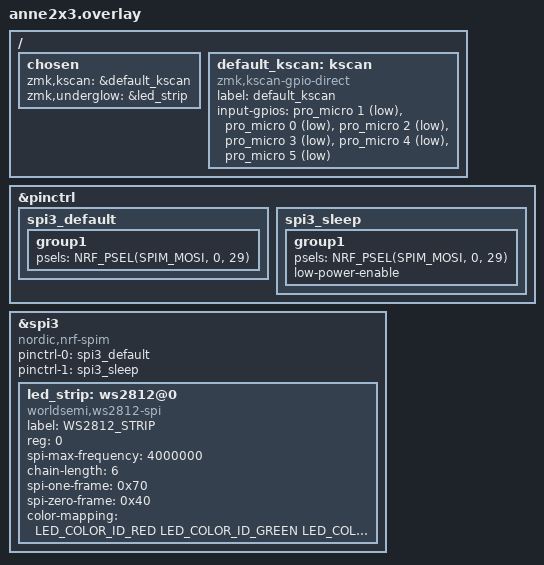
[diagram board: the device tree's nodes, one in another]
/*
 * Copyright (c) 2024 The ZMK Contributors
 *
 * SPDX-License-Identifier: MIT
 */

#include <dt-bindings/led/led.h> // Necesario para LED_COLOR_ID_XXX

/ {
    chosen {
        zmk,kscan = &default_kscan;
        zmk,underglow = &led_strip; // Apunta a la etiqueta de la tira de LEDs definida abajo
    };

    default_kscan: kscan {
        compatible = "zmk,kscan-gpio-direct";
        label = "default_kscan";
        input-gpios =
            <&pro_micro 1  (GPIO_ACTIVE_LOW | GPIO_PULL_UP)>,
            <&pro_micro 0  (GPIO_ACTIVE_LOW | GPIO_PULL_UP)>,
            <&pro_micro 2  (GPIO_ACTIVE_LOW | GPIO_PULL_UP)>,
            <&pro_micro 3  (GPIO_ACTIVE_LOW | GPIO_PULL_UP)>,
            <&pro_micro 4  (GPIO_ACTIVE_LOW | GPIO_PULL_UP)>,
            <&pro_micro 5  (GPIO_ACTIVE_LOW | GPIO_PULL_UP)>;
    };
};

// --- Sección para LEDs WS2812B usando driver SPI ---

// Configuración del pinctrl para el periférico SPI3
// Se asigna el pin P0.29 como MOSI para spi3.
&pinctrl {
    spi3_default: spi3_default {
        group1 {
            // P0.29 como MOSI (Master Out Slave In) del SPIM3
            psels = <NRF_PSEL(SPIM_MOSI, 0, 29)>; // <--- CORREGIDO A PIN 29
        };
    };

    spi3_sleep: spi3_sleep {
        group1 {
            psels = <NRF_PSEL(SPIM_MOSI, 0, 29)>; // <--- CORREGIDO A PIN 29
            low-power-enable; // Configuración para bajo consumo
        };
    };
};

// Habilitación y configuración del periférico SPI3
&spi3 {
    compatible = "nordic,nrf-spim"; // Compatible para el controlador SPIM de Nordic
    status = "okay"; // Habilitar el periférico SPI3

    // Asignar los pinctrl definidos arriba
    pinctrl-0 = <&spi3_default>;
    pinctrl-1 = <&spi3_sleep>;
    pinctrl-names = "default", "sleep";

    // Definición de la tira de LEDs WS2812 como un dispositivo en este bus SPI
    // La etiqueta "led_strip" es la importante para 'chosen'.
    led_strip: ws2812@0 { // El @0 es una convención para la dirección en el bus SPI
        compatible = "worldsemi,ws2812-spi"; // Driver para WS2812 vía SPI
        label = "WS2812_STRIP";

        /* Propiedades SPI */
        reg = <0>; /* Dirección del dispositivo en el bus SPI (ignorado pero necesario) */
        spi-max-frequency = <4000000>; /* 4MHz, común para WS2812 */

        /* Propiedades específicas de WS2812 */
        chain-length = <6>;         /* Número de LEDs */
        spi-one-frame = <0x70>;     /* Patrón de bits SPI para '1' lógico de WS2812 */
        spi-zero-frame = <0x40>;    /* Patrón de bits SPI para '0' lógico de WS2812 */
        color-mapping = <LED_COLOR_ID_RED LED_COLOR_ID_GREEN LED_COLOR_ID_BLUE>; /* Mapeo RGB */
    };
};
// --- Fin de la sección de LEDs ---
